# UHH_config register map
Vendor: Texas Instruments
Peripheral module from a debugger description file (folder omap36xx).
Registers are 32-bit, access per field, reset values left out (the file's numbers can be read two ways) unless marked. A register's access mark holds for its fields unless they carry their own. Offsets are as the file gives them; lines under a group give offsets from that group; [hi:lo] are bit positions; {n}, {i} and the like mark numbered series; 'fields as' and 'values as' point back to an identical list; <NAME> marks a mode.

## UHH_config
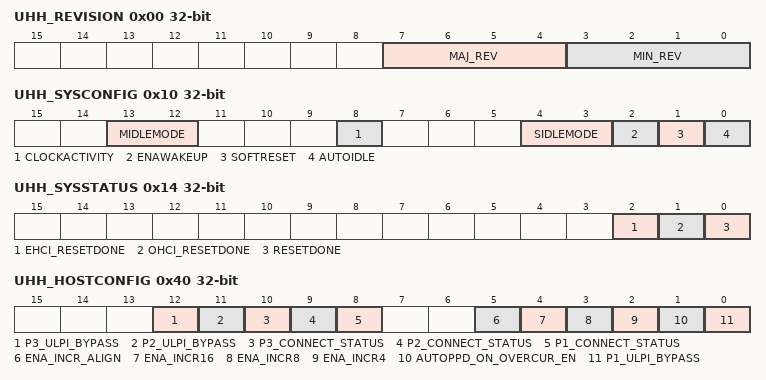
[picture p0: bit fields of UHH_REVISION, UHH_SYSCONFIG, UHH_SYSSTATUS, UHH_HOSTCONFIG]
0x00 UHH_REVISION ro — Standard revision number, BCD encoded Revision = <maj>.<min>
  [7:4] MAJ_REV — Major revision number 0..9
  [3:0] MIN_REV — Minor revision number 0..9
0x10 UHH_SYSCONFIG — Standard system configuration register
  [13:12] MIDLEMODE rw — Master interface power management control. Standby/wait control
    0=Force-standby mode. Mstandby asserted unconditionally; 1=No-standby mode. Mstandby never asserted.; 2=Smart-standby mode. Mstandby asserted when initiator activity stops
  [8] CLOCKACTIVITY rw — Control of clock internal gating while module is idle. One bit per clock, actual register width depends on the number of functional clocks controlled. Lower bit: Interface clockUpper bits (if any): Functional clocks 1: Clock is kept on during idle0: Clock is switched off during idle
  [4:3] SIDLEMODE rw — Slave interface power management control. Idle Req/ack control
    0=Force-Idle mode. Sidleack asserted after Idlereq assertion; 1=No-idle mode. Sidleack never asserted.; 2=Smart-idle mode. Sidleack asserted upon Idlereq assertion, after target activity is over
  [2] ENAWAKEUP rw — Asynchronous wakeup generation control (Swakeup)
    0=Wakeup generation disabled; 1=Wakeup generation enabled
  [1] SOFTRESET wo — Module software reset
    0=No effect; 1=Starts softreset sequence
  [0] AUTOIDLE rw — Internal autogating control
    0=Clock always running; 1=When no activity on L3 interconnect, clock is cut off
0x14 UHH_SYSSTATUS ro — Standard system status register
  [2] EHCI_RESETDONE — Indicated when the EHCI HS host is out of reset
  [1] OHCI_RESETDONE — Indicates when the OHCI FS/LS host is out of reset
  [0] RESETDONE — Indicates when the USB Host has come out of reset
    0=Reset is ongoing; 1=Reset is done
0x40 UHH_HOSTCONFIG — Static configuration of the OTG controller host
  [12] P3_ULPI_BYPASS rw — Host controller (root hub) port 3 control.
    0=ULPI port 3 is active (and UTMI port 3 is inactive); 1=UTMI port 3 is active (and ULPI port 3 is inactive)
  [11] P2_ULPI_BYPASS rw — Host controller (root hub) port 2 control.
    0=ULPI port 2 is active (and UTMI port 2 is inactive); 1=UTMI port 2 is active (and ULPI port 2 is inactive)
  [10] P3_CONNECT_STATUS rw — Connection status for port 3.
    0=USB port 3 is disconnected; 1=USB port 3 is connected and in use (also the default state)
  [9] P2_CONNECT_STATUS rw — Connection status for port 2.
    0=USB port 2 is disconnected; 1=USB port 2 is connected and in use (also the default state)
  [8] P1_CONNECT_STATUS rw — Connection status for port 1.
    0=USB port 1 is disconnected; 1=USB port 1 is connected and in use (also the default state)
  [5] ENA_INCR_ALIGN rw — Force alignment of bursts to the respective burst-size boundaries
    0=Disable burst type; 1=Enable burst type
  [4] ENA_INCR16 rw — Control the use of INCR16-type bursts (in AHB sense)
    0=Disable burst type; 1=Enable burst type
  [3] ENA_INCR8 rw — Control the use of INCR8-type bursts (in AHB sense)
    0=Disable burst type; 1=Enable burst type
  [2] ENA_INCR4 rw — Control the use of INCR4-type bursts (in AHB sense)
    0=Disable burst type; 1=Enable burst type
  [1] AUTOPPD_ON_OVERCUR_EN rw — Configure reaction upon port overcurrent condition
    0=Port remains on upon overcurrent; 1=Port is powered down automatically upon overcurrent Note: The bit must not be used, and is always written to with its default (reset) value as the hardware overcurrent inputs are tied off at device level
  [0] P1_ULPI_BYPASS rw — Host controller (root hub) port 1 control.
    0=ULPI port 1 is active (and UTMI port 1 is inactive); 1=UTMI port 1 is active (and ULPI port 1 is inactive)
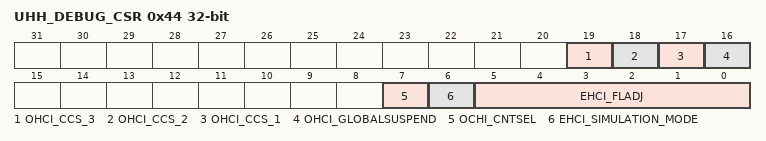
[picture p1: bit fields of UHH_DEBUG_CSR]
0x44 UHH_DEBUG_CSR — Debug control and status for the EHCI, OHCI hosts.
  [19] OHCI_CCS_3 ro — Current Connect Status of port 3
    0=No periph connected; 1=Periph connected
  [18] OHCI_CCS_2 ro — Current Connect Status of port 2
    0=No periph connected; 1=Periph connected
  [17] OHCI_CCS_1 ro — Current Connect Status of port 1
    0=No periph connected; 1=Periph connected
  [16] OHCI_GLOBALSUSPEND ro — OHCI global suspend status, asserted 5ms after the suspend order.
    0=Host is not suspended; 1=Host is suspended
  [7] OCHI_CNTSEL rw — Selection of a shorter '1 ms' counter in OHCI host, to speed up long USB phases like reset, resume, etc (Used only for simulation.)
    0=Functional mode, 1ms = 12,000 x 12 MHz cycles; 1=Simulation mode, 1ms = 7 x 12 MHz cycles = 583 ns
  [6] EHCI_SIMULATION_MODE rw — Sets the PHY to non-driving mode. (Used only for simulation.)
    0=Functional mode; 1=PHY set to non-driving
  [5:0] EHCI_FLADJ rw — EHCI host frame length adjust. Modify only when EHCI bitfieldUSBSTS.HCHalted = 1Field value + 59,488 = 60,000 by default= number of 60 MHz UTMI/ULPI clock cycles per 1 ms USB frame= number of 480 MHz HS bits per 125 us HS USB microframe
